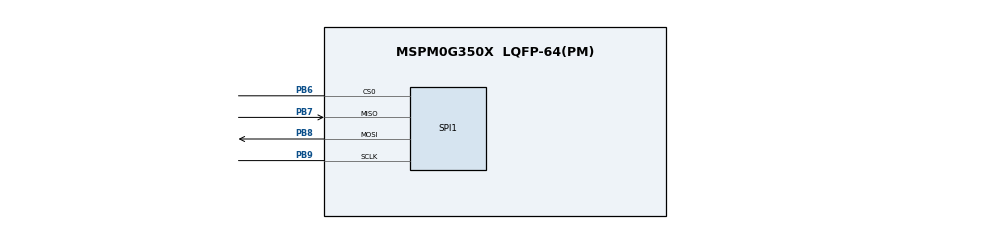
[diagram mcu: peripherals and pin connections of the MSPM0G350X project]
// @cliArgs --device "MSPM0G350X" --package "LQFP-64(PM)" --part "Default"
// @cliArgs --board /ti/boards/LP_MSPM0G3507 --rtos nortos

/**
 * Import the modules used in this configuration.
 */
const SPI  = scripting.addModule("/ti/driverlib/SPI", {}, false);
const SPI1 = SPI.addInstance();
const SYSCTL = scripting.addModule("/ti/driverlib/SYSCTL");

/**
 * Write custom configuration values to the imported modules.
 */
SPI1.$name                      = "SPI_0";
SPI1.mode                       = "PERIPHERAL";
SPI1.enabledInterrupts          = ["RX"];
SPI1.txFifoThreshold            = "DL_SPI_TX_FIFO_LEVEL_1_2_EMPTY";
SPI1.rxFifoThreshold            = "DL_SPI_RX_FIFO_LEVEL_1_4_FULL";
SPI1.peripheral.$assign         = "SPI1";
SPI1.peripheral.sclkPin.$assign = "PB9";
SPI1.peripheral.mosiPin.$assign = "PB8";
SPI1.peripheral.misoPin.$assign = "PB7";
SPI1.peripheral.cs0Pin.$assign  = "PB6";

const Board = scripting.addModule("/ti/driverlib/Board", {}, false);
SYSCTL.clockTreeEn = true;
